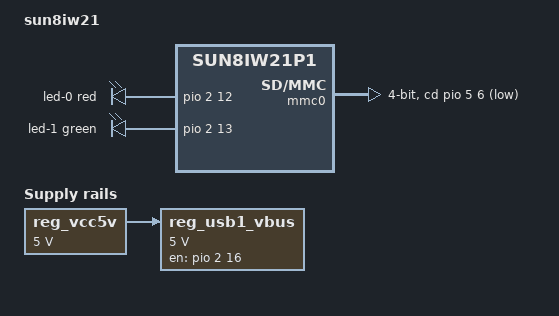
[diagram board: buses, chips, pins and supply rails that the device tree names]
// SPDX-License-Identifier: (GPL-2.0+ or MIT)
/*
 * Allwinner Technology CO., Ltd. sun8iw21p1 platform
 *
 * modify base on juno.dts
 */

/dts-v1/;

#include "sun8iw21p1.dtsi"

/ {
	model = "sun8iw21";
	compatible = "allwinner,v853s3", "arm,sun8iw21p1";

	aliases {
		serial0 = &uart0;
	};

	chosen {
		stdout-path = "serial0:115200n8";
	};

	leds {
		compatible = "gpio-leds";

		led-0 {
			function = LED_FUNCTION_POWER;
			color = <LED_COLOR_ID_RED>;
			gpios = <&pio 2 12 GPIO_ACTIVE_HIGH>; /* PC12 */
			default-state = "on";
		};

		led-1 {
			function = LED_FUNCTION_STATUS;
			color = <LED_COLOR_ID_GREEN>;
			gpios = <&pio 2 13 GPIO_ACTIVE_HIGH>; /* PC13 */
		};
	};

	reg_vcc5v: vcc5v {
		/* board wide 5V supply directly from the USB-C socket */
		compatible = "regulator-fixed";
		regulator-name = "vcc-5v";
		regulator-min-microvolt = <5000000>;
		regulator-max-microvolt = <5000000>;
		regulator-always-on;
	};

	reg_usb1_vbus: regulator-usb1-vbus {
		compatible = "regulator-fixed";
		regulator-name = "usb1-vbus";
		regulator-min-microvolt = <5000000>;
		regulator-max-microvolt = <5000000>;
		vin-supply = <&reg_vcc5v>;
		enable-active-high;
		gpio = <&pio 2 16 GPIO_ACTIVE_HIGH>; /* PC16 */
	};
};

&mmc0 {
	cd-gpios = <&pio 5 6 GPIO_ACTIVE_LOW>;	/* PF6 */
	bus-width = <4>;
	status = "okay";
};

&spi0  {

};

&uart0 {

};

&platform {
	debug_mode = <6>;
};
